# cslr_pwrdwnL2 register map
Vendor: Texas Instruments
Peripheral module from a debugger description file (folder TCI6484_C6457).
Registers are 32-bit, access not given, reset 0x0 unless marked. A register's access mark holds for its fields unless they carry their own. Offsets are as the file gives them; lines under a group give offsets from that group; [hi:lo] are bit positions; {n}, {i} and the like mark numbered series; 'fields as' and 'values as' point back to an identical list; <NAME> marks a mode.

## L2PWRDWN — Power Down
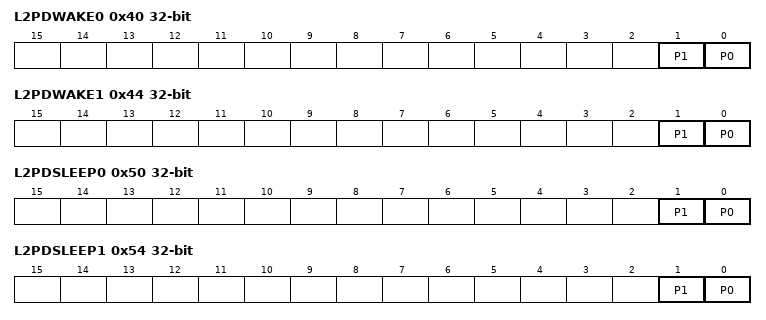
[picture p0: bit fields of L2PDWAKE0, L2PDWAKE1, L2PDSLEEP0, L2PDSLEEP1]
0x40 L2PDWAKE0 — Level 2 Power Down Wake 0 Register
  [1] P1 rw — Wakes-up Page 1, Port 0 or 1. Writing 0 to this field has no effect on Page 1. Writing a 1 to this field wakes-up the page from the power-down state.
    0=DISABLE (No effect on page 1); 1=ENABLE (Wakes-up the page from the power-down state)
  [0] P0 rw — Wakes-up Page 0, Port 0 or 1. Writing 0 to this field has no effect on Page 0. Writing a 1 to this field wakes-up the page from the power-down state.
    0=DISABLE (No effect on page 0); 1=ENABLE (Wakes-up the page from the power-down state)
0x44 L2PDWAKE1 — Level 2 Power Down Wake 1 Register
  fields as L2PDWAKE0
0x50 L2PDSLEEP0 — Level 2 Power Down Sleep 0 Register
  [1] P1 rw — Places page 1, Port 0 or 1 in power-down state Writing 0 to this field has no effect on page 1 Writing 1 to this field places the page in power-down state
    0=DISABLE (No effect on page 1); 1=ENABLE (Places the page in power-down state)
  [0] P0 rw — Places page 0, Port 0 or 1 in power-down state Writing 0 to this field has no effect on page 0 Writing 1 to this field places the page in power-down state
    0=DISABLE (No effect on page 0); 1=ENABLE (Places the page in power-down state)
0x54 L2PDSLEEP1 — Level 2 Power Down Sleep 1 Register
  fields as L2PDSLEEP0
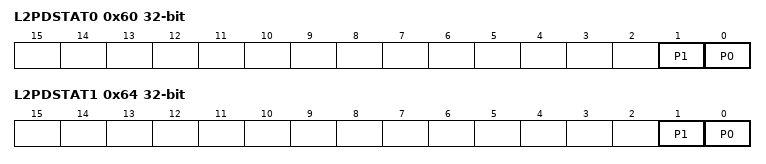
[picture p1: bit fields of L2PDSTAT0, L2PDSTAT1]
0x60 L2PDSTAT0 — Level 2 Power Down Status 0 Register
  [1] P1 ro — Reports power-down status for Page 1, port 0 or 1 Reading 0 from this field means Page 1 is in normal state Reading 1 from this field means Page 1 is in power-down state
  [0] P0 ro — Reports power-down status for Page 0, port 0 or 1 Reading 0 from this field means Page 0 is in normal state Reading 1 from this field means Page 0 is in power-down state
0x64 L2PDSTAT1 — Level 2 Power Down Status 1 Register
  fields as L2PDSTAT0
